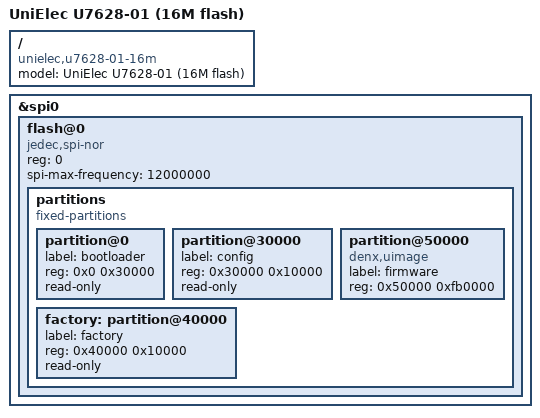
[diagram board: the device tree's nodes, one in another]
// SPDX-License-Identifier: BSD-3-Clause
/*
 *  Copyright(c) 2017 Kristian Evensen <kristian.evensen@gmail.com>.
 *  Copyright(c) 2017 Piotr Dymacz <pepe2k@gmail.com>.
 *  All rights reserved.
 */

#include "mt7628an_unielec_u7628-01.dtsi"

/ {
	compatible = "unielec,u7628-01-16m", "unielec,u7628-01", "mediatek,mt7628an-soc";
	model = "UniElec U7628-01 (16M flash)";
};

&spi0 {
	status = "okay";

	flash@0 {
		compatible = "jedec,spi-nor";
		reg = <0>;
		spi-max-frequency = <12000000>;

		partitions {
			compatible = "fixed-partitions";
			#address-cells = <1>;
			#size-cells = <1>;

			partition@0 {
				label = "bootloader";
				reg = <0x0 0x30000>;
				read-only;
			};

			partition@30000 {
				label = "config";
				reg = <0x30000 0x10000>;
				read-only;
			};

			factory: partition@40000 {
				label = "factory";
				reg = <0x40000 0x10000>;
				read-only;
			};

			partition@50000 {
				compatible = "denx,uimage";
				label = "firmware";
				reg = <0x50000 0xfb0000>;
			};
		};
	};
};
